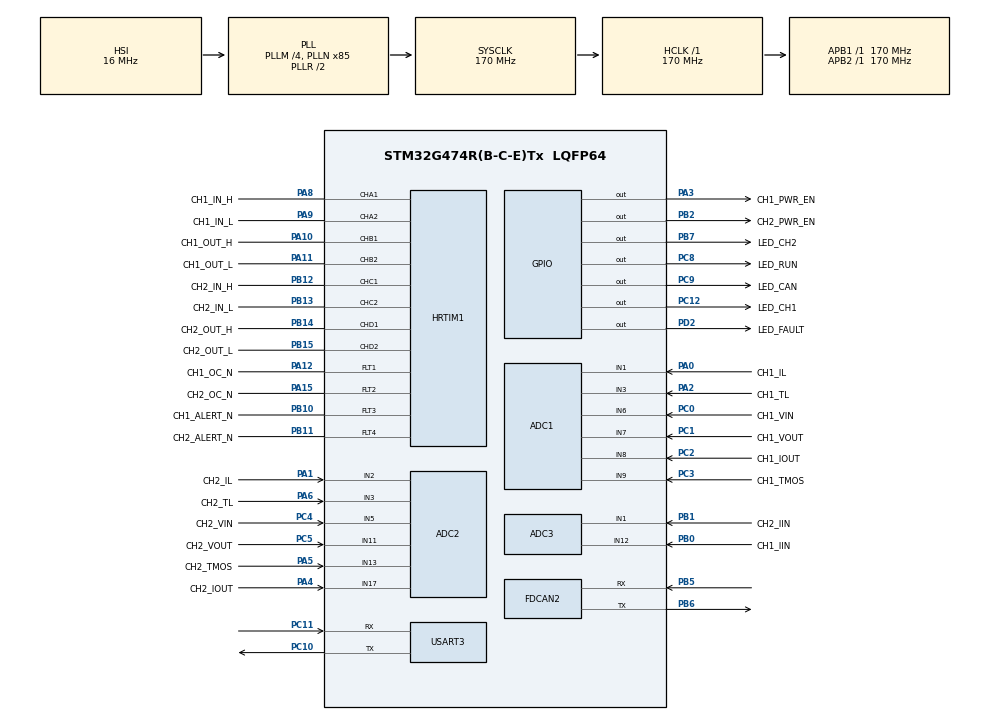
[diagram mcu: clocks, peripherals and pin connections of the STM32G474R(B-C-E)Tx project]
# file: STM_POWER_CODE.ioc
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ADC1.Channel-0\#ChannelRegularConversion=ADC_CHANNEL_6
ADC1.Channel-1\#ChannelRegularConversion=ADC_CHANNEL_7
ADC1.Channel-2\#ChannelRegularConversion=ADC_CHANNEL_8
ADC1.Channel-3\#ChannelRegularConversion=ADC_CHANNEL_9
ADC1.Channel-4\#ChannelRegularConversion=ADC_CHANNEL_3
ADC1.ClockPrescaler=ADC_CLOCK_ASYNC_DIV6
ADC1.ContinuousConvMode=DISABLE
ADC1.DMAContinuousRequests=ENABLE
ADC1.DiscontinuousConvMode=ENABLE
ADC1.EOCSelection=ADC_EOC_SEQ_CONV
ADC1.EnableInjectedConversion=ENABLE
ADC1.ExternalTrigConv=ADC_EXTERNALTRIG_HRTIM_TRG1
ADC1.ExternalTrigInjecConv=ADC_EXTERNALTRIGINJEC_HRTIM_TRG2
ADC1.GainCompensation=0
ADC1.InjNumberOfConversion=1
ADC1.InjectedChannel-6\#ChannelInjectedConversion=ADC_CHANNEL_1
ADC1.InjectedOffsetNumber-6\#ChannelInjectedConversion=ADC_OFFSET_NONE
ADC1.InjectedRank-6\#ChannelInjectedConversion=1
ADC1.InjectedSamplingTime-6\#ChannelInjectedConversion=ADC_SAMPLETIME_24CYCLES_5
ADC1.NbrOfConversion=5
ADC1.NbrOfConversionFlag=1
ADC1.OffsetNumber-0\#ChannelRegularConversion=ADC_OFFSET_NONE
ADC1.OffsetNumber-1\#ChannelRegularConversion=ADC_OFFSET_NONE
ADC1.OffsetNumber-2\#ChannelRegularConversion=ADC_OFFSET_NONE
ADC1.OffsetNumber-3\#ChannelRegularConversion=ADC_OFFSET_NONE
ADC1.OffsetNumber-4\#ChannelRegularConversion=ADC_OFFSET_NONE
ADC1.Rank-0\#ChannelRegularConversion=1
ADC1.Rank-1\#ChannelRegularConversion=2
ADC1.Rank-2\#ChannelRegularConversion=3
ADC1.Rank-3\#ChannelRegularConversion=4
ADC1.Rank-4\#ChannelRegularConversion=5
ADC1.Rank1_Channel=ADC_CHANNEL_1
ADC1.SamplingTime-0\#ChannelRegularConversion=ADC_SAMPLETIME_47CYCLES_5
ADC1.SamplingTime-1\#ChannelRegularConversion=ADC_SAMPLETIME_47CYCLES_5
ADC1.SamplingTime-2\#ChannelRegularConversion=ADC_SAMPLETIME_24CYCLES_5
ADC1.SamplingTime-3\#ChannelRegularConversion=ADC_SAMPLETIME_92CYCLES_5
ADC1.SamplingTime-4\#ChannelRegularConversion=ADC_SAMPLETIME_92CYCLES_5
ADC1.master=1
ADC2.Channel-1\#ChannelRegularConversion=ADC_CHANNEL_5
ADC2.Channel-2\#ChannelRegularConversion=ADC_CHANNEL_11
ADC2.Channel-3\#ChannelRegularConversion=ADC_CHANNEL_17
ADC2.Channel-4\#ChannelRegularConversion=ADC_CHANNEL_13
ADC2.Channel-5\#ChannelRegularConversion=ADC_CHANNEL_3
ADC2.ClockPrescaler=ADC_CLOCK_ASYNC_DIV6
ADC2.DMAContinuousRequests=ENABLE
ADC2.DiscontinuousConvMode=ENABLE
ADC2.EOCSelection=ADC_EOC_SEQ_CONV
ADC2.EnableInjectedConversion=ENABLE
ADC2.ExternalTrigConv=ADC_EXTERNALTRIG_HRTIM_TRG1
ADC2.ExternalTrigInjecConv=ADC_EXTERNALTRIGINJEC_HRTIM_TRG2
ADC2.InjNumberOfConversion=1
ADC2.InjectedChannel-7\#ChannelInjectedConversion=ADC_CHANNEL_2
ADC2.InjectedOffsetNumber-7\#ChannelInjectedConversion=ADC_OFFSET_NONE
ADC2.InjectedRank-7\#ChannelInjectedConversion=1
ADC2.InjectedSamplingTime-7\#ChannelInjectedConversion=ADC_SAMPLETIME_24CYCLES_5
ADC2.NbrOfConversion=5
ADC2.NbrOfConversionFlag=1
ADC2.OffsetNumber-1\#ChannelRegularConversion=ADC_OFFSET_NONE
ADC2.OffsetNumber-2\#ChannelRegularConversion=ADC_OFFSET_NONE
ADC2.OffsetNumber-3\#ChannelRegularConversion=ADC_OFFSET_NONE
ADC2.OffsetNumber-4\#ChannelRegularConversion=ADC_OFFSET_NONE
ADC2.OffsetNumber-5\#ChannelRegularConversion=ADC_OFFSET_NONE
ADC2.Rank-1\#ChannelRegularConversion=1
ADC2.Rank-2\#ChannelRegularConversion=2
ADC2.Rank-3\#ChannelRegularConversion=3
ADC2.Rank-4\#ChannelRegularConversion=4
ADC2.Rank-5\#ChannelRegularConversion=5
ADC2.Rank1_Channel=ADC_CHANNEL_2
ADC2.SamplingTime-1\#ChannelRegularConversion=ADC_SAMPLETIME_47CYCLES_5
ADC2.SamplingTime-2\#ChannelRegularConversion=ADC_SAMPLETIME_47CYCLES_5
ADC2.SamplingTime-3\#ChannelRegularConversion=ADC_SAMPLETIME_24CYCLES_5
ADC2.SamplingTime-4\#ChannelRegularConversion=ADC_SAMPLETIME_92CYCLES_5
ADC2.SamplingTime-5\#ChannelRegularConversion=ADC_SAMPLETIME_92CYCLES_5
ADC3.Channel-0\#ChannelRegularConversion=ADC_CHANNEL_12
ADC3.Channel-1\#ChannelRegularConversion=ADC_CHANNEL_1
ADC3.ClockPrescaler=ADC_CLOCK_ASYNC_DIV6
ADC3.DMAContinuousRequests=ENABLE
ADC3.DiscontinuousConvMode=DISABLE
ADC3.EOCSelection=ADC_EOC_SEQ_CONV
ADC3.ExternalTrigConv=ADC_EXTERNALTRIG_T7_TRGO
ADC3.NbrOfConversion=2
ADC3.NbrOfConversionFlag=1
ADC3.OffsetNumber-0\#ChannelRegularConversion=ADC_OFFSET_NONE
ADC3.OffsetNumber-1\#ChannelRegularConversion=ADC_OFFSET_NONE
ADC3.Rank-0\#ChannelRegularConversion=1
ADC3.Rank-1\#ChannelRegularConversion=2
ADC3.SamplingTime-0\#ChannelRegularConversion=ADC_SAMPLETIME_247CYCLES_5
ADC3.SamplingTime-1\#ChannelRegularConversion=ADC_SAMPLETIME_247CYCLES_5
ADC3.master=1
Dma.ADC1.2.Direction=DMA_PERIPH_TO_MEMORY
Dma.ADC1.2.EventEnable=DISABLE
Dma.ADC1.2.Instance=DMA1_Channel3
Dma.ADC1.2.MemDataAlignment=DMA_MDATAALIGN_HALFWORD
Dma.ADC1.2.MemInc=DMA_MINC_ENABLE
Dma.ADC1.2.Mode=DMA_CIRCULAR
Dma.ADC1.2.PeriphDataAlignment=DMA_PDATAALIGN_HALFWORD
Dma.ADC1.2.PeriphInc=DMA_PINC_DISABLE
Dma.ADC1.2.Polarity=HAL_DMAMUX_REQ_GEN_RISING
Dma.ADC1.2.Priority=DMA_PRIORITY_HIGH
Dma.ADC1.2.RequestNumber=1
Dma.ADC1.2.SignalID=NONE
Dma.ADC1.2.SyncEnable=DISABLE
Dma.ADC1.2.SyncPolarity=HAL_DMAMUX_SYNC_NO_EVENT
Dma.ADC1.2.SyncRequestNumber=1
Dma.ADC1.2.SyncSignalID=NONE
Dma.ADC2.3.Direction=DMA_PERIPH_TO_MEMORY
Dma.ADC2.3.EventEnable=DISABLE
Dma.ADC2.3.Instance=DMA1_Channel4
Dma.ADC2.3.MemDataAlignment=DMA_MDATAALIGN_HALFWORD
Dma.ADC2.3.MemInc=DMA_MINC_ENABLE
Dma.ADC2.3.Mode=DMA_CIRCULAR
Dma.ADC2.3.PeriphDataAlignment=DMA_PDATAALIGN_HALFWORD
Dma.ADC2.3.PeriphInc=DMA_PINC_DISABLE
Dma.ADC2.3.Polarity=HAL_DMAMUX_REQ_GEN_RISING
Dma.ADC2.3.Priority=DMA_PRIORITY_HIGH
Dma.ADC2.3.RequestNumber=1
Dma.ADC2.3.SignalID=NONE
Dma.ADC2.3.SyncEnable=DISABLE
Dma.ADC2.3.SyncPolarity=HAL_DMAMUX_SYNC_NO_EVENT
Dma.ADC2.3.SyncRequestNumber=1
Dma.ADC2.3.SyncSignalID=NONE
Dma.ADC3.4.Direction=DMA_PERIPH_TO_MEMORY
Dma.ADC3.4.EventEnable=DISABLE
Dma.ADC3.4.Instance=DMA1_Channel5
Dma.ADC3.4.MemDataAlignment=DMA_MDATAALIGN_HALFWORD
Dma.ADC3.4.MemInc=DMA_MINC_ENABLE
Dma.ADC3.4.Mode=DMA_CIRCULAR
Dma.ADC3.4.PeriphDataAlignment=DMA_PDATAALIGN_HALFWORD
Dma.ADC3.4.PeriphInc=DMA_PINC_DISABLE
Dma.ADC3.4.Polarity=HAL_DMAMUX_REQ_GEN_RISING
Dma.ADC3.4.Priority=DMA_PRIORITY_HIGH
Dma.ADC3.4.RequestNumber=1
Dma.ADC3.4.SignalID=NONE
Dma.ADC3.4.SyncEnable=DISABLE
Dma.ADC3.4.SyncPolarity=HAL_DMAMUX_SYNC_NO_EVENT
Dma.ADC3.4.SyncRequestNumber=1
Dma.ADC3.4.SyncSignalID=NONE
Dma.Request0=USART3_RX
Dma.Request1=USART3_TX
Dma.Request2=ADC1
Dma.Request3=ADC2
Dma.Request4=ADC3
Dma.USART3_RX.0.Direction=DMA_PERIPH_TO_MEMORY
Dma.USART3_RX.0.EventEnable=DISABLE
Dma.USART3_RX.0.Instance=DMA1_Channel1
Dma.USART3_RX.0.MemDataAlignment=DMA_MDATAALIGN_BYTE
Dma.USART3_RX.0.MemInc=DMA_MINC_ENABLE
Dma.USART3_RX.0.Mode=DMA_CIRCULAR
Dma.USART3_RX.0.PeriphDataAlignment=DMA_PDATAALIGN_BYTE
Dma.USART3_RX.0.PeriphInc=DMA_PINC_DISABLE
Dma.USART3_RX.0.Polarity=HAL_DMAMUX_REQ_GEN_RISING
Dma.USART3_RX.0.Priority=DMA_PRIORITY_MEDIUM
Dma.USART3_RX.0.RequestNumber=1
Dma.USART3_RX.0.SignalID=NONE
Dma.USART3_RX.0.SyncEnable=DISABLE
Dma.USART3_RX.0.SyncPolarity=HAL_DMAMUX_SYNC_NO_EVENT
Dma.USART3_RX.0.SyncRequestNumber=1
Dma.USART3_RX.0.SyncSignalID=NONE
Dma.USART3_TX.1.Direction=DMA_MEMORY_TO_PERIPH
Dma.USART3_TX.1.EventEnable=DISABLE
Dma.USART3_TX.1.Instance=DMA1_Channel2
Dma.USART3_TX.1.MemDataAlignment=DMA_MDATAALIGN_BYTE
Dma.USART3_TX.1.MemInc=DMA_MINC_ENABLE
Dma.USART3_TX.1.Mode=DMA_NORMAL
Dma.USART3_TX.1.PeriphDataAlignment=DMA_PDATAALIGN_BYTE
Dma.USART3_TX.1.PeriphInc=DMA_PINC_DISABLE
Dma.USART3_TX.1.Polarity=HAL_DMAMUX_REQ_GEN_RISING
Dma.USART3_TX.1.Priority=DMA_PRIORITY_LOW
Dma.USART3_TX.1.RequestNumber=1
Dma.USART3_TX.1.SignalID=NONE
Dma.USART3_TX.1.SyncEnable=DISABLE
Dma.USART3_TX.1.SyncPolarity=HAL_DMAMUX_SYNC_NO_EVENT
Dma.USART3_TX.1.SyncRequestNumber=1
Dma.USART3_TX.1.SyncSignalID=NONE
FDCAN2.CalculateBaudRateNominal=499999
FDCAN2.CalculateTimeBitNominal=2000
FDCAN2.CalculateTimeQuantumNominal=23.529411764705884
FDCAN2.NominalPrescaler=1
FDCAN2.NominalSyncJumpWidth=8
FDCAN2.NominalTimeSeg1=67
FDCAN2.NominalTimeSeg2=17
FDCAN2.StdFiltersNbr=1
FREERTOS.Tasks01=defaultTask,24,1024,StartDefaultTask,Default,NULL,Dynamic,NULL,NULL
FREERTOS.configCHECK_FOR_STACK_OVERFLOW=2
FREERTOS.configTOTAL_HEAP_SIZE=16384
FREERTOS.configUSE_MALLOC_FAILED_HOOK=1
HRTIM1.ADCTrigger1_Source1=HRTIM_ADCTRIGGEREVENT13_TIMERE_CMP3
HRTIM1.ADCTrigger2_Source1=HRTIM_ADCTRIGGEREVENT24_TIMERE_CMP2
HRTIM1.ADCTrigger_Id1=HRTIM_ADCTRIGGER_1
HRTIM1.ADCTrigger_Id2=HRTIM_ADCTRIGGER_2
HRTIM1.AutoDelayedMode2-No_output_TE=HRTIM_AUTODELAYEDMODE_REGULAR
HRTIM1.BlankingSourceFaultLine1=__NULL
HRTIM1.BlankingSourceFaultLine2=__NULL
HRTIM1.BlankingSourceFaultLine3=__NULL
HRTIM1.BlankingSourceFaultLine4=__NULL
HRTIM1.CompareUnit1-Output_TA1TA2=HRTIM_COMPAREUNIT_1
HRTIM1.CompareUnit1-Output_TB1TB2=HRTIM_COMPAREUNIT_1
HRTIM1.CompareUnit1-Output_TC1TC2=HRTIM_COMPAREUNIT_1
HRTIM1.CompareUnit1-Output_TD1TD2=HRTIM_COMPAREUNIT_1
HRTIM1.CompareUnit2-No_output_TE=HRTIM_COMPAREUNIT_2
HRTIM1.CompareUnit3-No_output_TE=HRTIM_COMPAREUNIT_3
HRTIM1.CompareValue1-Output_TA1TA2=0x2A80
HRTIM1.CompareValue1-Output_TB1TB2=0x2A80
HRTIM1.CompareValue1-Output_TC1TC2=0x2A80
HRTIM1.CompareValue1-Output_TD1TD2=0x2A80
HRTIM1.CompareValue2-No_output_TE=0x7F80
HRTIM1.CompareValue3-No_output_TE=0x2A80
HRTIM1.DeadTimeInsertion-Output_TA1TA2=HRTIM_TIMDEADTIMEINSERTION_ENABLED
HRTIM1.DeadTimeInsertion-Output_TB1TB2=HRTIM_TIMDEADTIMEINSERTION_ENABLED
HRTIM1.DeadTimeInsertion-Output_TC1TC2=HRTIM_TIMDEADTIMEINSERTION_ENABLED
HRTIM1.DeadTimeInsertion-Output_TD1TD2=HRTIM_TIMDEADTIMEINSERTION_ENABLED
HRTIM1.FallingValue-Output_TA1TA2=0x014
HRTIM1.FallingValue-Output_TB1TB2=0x014
HRTIM1.FallingValue-Output_TC1TC2=0x014
HRTIM1.FallingValue-Output_TD1TD2=0x014
HRTIM1.FaultEnable_Source1-Output_TA1TA2=HRTIM_TIMFAULTENABLE_FAULT1
HRTIM1.FaultEnable_Source1-Output_TB1TB2=HRTIM_TIMFAULTENABLE_FAULT1
HRTIM1.FaultEnable_Source1-Output_TC1TC2=HRTIM_TIMFAULTENABLE_FAULT2
HRTIM1.FaultEnable_Source1-Output_TD1TD2=HRTIM_TIMFAULTENABLE_FAULT2
HRTIM1.FaultEnable_Source2-Output_TA1TA2=HRTIM_TIMFAULTENABLE_FAULT3
HRTIM1.FaultEnable_Source2-Output_TB1TB2=HRTIM_TIMFAULTENABLE_FAULT3
HRTIM1.FaultEnable_Source2-Output_TC1TC2=HRTIM_TIMFAULTENABLE_FAULT4
HRTIM1.FaultEnable_Source2-Output_TD1TD2=HRTIM_TIMFAULTENABLE_FAULT4
HRTIM1.FaultLevel1-Output_TA1TA2=HRTIM_OUTPUTFAULTLEVEL_INACTIVE
HRTIM1.FaultLevel1-Output_TB1TB2=HRTIM_OUTPUTFAULTLEVEL_INACTIVE
HRTIM1.FaultLevel1-Output_TC1TC2=HRTIM_OUTPUTFAULTLEVEL_INACTIVE
HRTIM1.FaultLevel1-Output_TD1TD2=HRTIM_OUTPUTFAULTLEVEL_INACTIVE
HRTIM1.FaultLevel2-Output_TA1TA2=HRTIM_OUTPUTFAULTLEVEL_INACTIVE
HRTIM1.FaultLevel2-Output_TB1TB2=HRTIM_OUTPUTFAULTLEVEL_INACTIVE
HRTIM1.FaultLevel2-Output_TC1TC2=HRTIM_OUTPUTFAULTLEVEL_INACTIVE
HRTIM1.FaultLevel2-Output_TD1TD2=HRTIM_OUTPUTFAULTLEVEL_INACTIVE
HRTIM1.HRTIMInterruptResquests1=HRTIM_IT_FLT1
HRTIM1.HRTIMInterruptResquests2=HRTIM_IT_FLT2
HRTIM1.HRTIMInterruptResquests3=HRTIM_IT_FLT3
HRTIM1.HRTIMInterruptResquests4=HRTIM_IT_FLT4
HRTIM1.IdleMode1-Output_TA1TA2=HRTIM_OUTPUTIDLEMODE_IDLE
HRTIM1.IdleMode1-Output_TB1TB2=HRTIM_OUTPUTIDLEMODE_IDLE
HRTIM1.IdleMode1-Output_TC1TC2=HRTIM_OUTPUTIDLEMODE_IDLE
HRTIM1.IdleMode1-Output_TD1TD2=HRTIM_OUTPUTIDLEMODE_IDLE
HRTIM1.IdleMode2-Output_TA1TA2=HRTIM_OUTPUTIDLEMODE_IDLE
HRTIM1.IdleMode2-Output_TB1TB2=HRTIM_OUTPUTIDLEMODE_IDLE
HRTIM1.IdleMode2-Output_TC1TC2=HRTIM_OUTPUTIDLEMODE_IDLE
HRTIM1.IdleMode2-Output_TD1TD2=HRTIM_OUTPUTIDLEMODE_IDLE
HRTIM1.NumberADCTriggerSource1=1
HRTIM1.NumberADCTriggerSource2=1
HRTIM1.NumberFaultEnable-Output_TA1TA2=2
HRTIM1.NumberFaultEnable-Output_TB1TB2=2
HRTIM1.NumberFaultEnable-Output_TC1TC2=2
HRTIM1.NumberFaultEnable-Output_TD1TD2=2
HRTIM1.NumberResetSource1-Output_TA1TA2=1
HRTIM1.NumberResetSource1-Output_TB1TB2=1
HRTIM1.NumberResetSource1-Output_TC1TC2=1
HRTIM1.NumberResetSource1-Output_TD1TD2=1
HRTIM1.NumberResetTrigger-Output_TA1TA2=1
HRTIM1.NumberResetTrigger-Output_TB1TB2=1
HRTIM1.NumberResetTrigger-Output_TC1TC2=1
HRTIM1.NumberResetTrigger-Output_TD1TD2=1
HRTIM1.NumberSetSource1-Output_TA1TA2=1
HRTIM1.NumberSetSource1-Output_TB1TB2=1
HRTIM1.NumberSetSource1-Output_TC1TC2=1
HRTIM1.NumberSetSource1-Output_TD1TD2=1
HRTIM1.NumberUpdateTrigger-Output_TA1TA2=1
HRTIM1.NumberUpdateTrigger-Output_TB1TB2=1
HRTIM1.NumberUpdateTrigger-Output_TC1TC2=1
HRTIM1.NumberUpdateTrigger-Output_TD1TD2=1
HRTIM1.ORingUpdateSource_ADCTrigger1=HRTIM_ADCTRIGGERUPDATE_TIMER_E
HRTIM1.ORingUpdateSource_ADCTrigger2=HRTIM_ADCTRIGGERUPDATE_TIMER_E
HRTIM1.Periode_MASTER=0x5500
HRTIM1.Periode_TA=0x5500
HRTIM1.Periode_TB=0x5500
HRTIM1.Periode_TC=0x5500
HRTIM1.Periode_TD=0x5500
HRTIM1.Periode_TE=0xAA00
HRTIM1.Polarity_FaultLine1=HRTIM_FAULTPOLARITY_LOW
HRTIM1.Polarity_FaultLine2=HRTIM_FAULTPOLARITY_LOW
HRTIM1.Polarity_FaultLine3=HRTIM_FAULTPOLARITY_LOW
HRTIM1.Polarity_FaultLine4=HRTIM_FAULTPOLARITY_LOW
HRTIM1.PreloadEnable-MasterTimer=HRTIM_PRELOAD_ENABLED
HRTIM1.PreloadEnable-Output_TA1TA2=HRTIM_PRELOAD_ENABLED
HRTIM1.PreloadEnable-Output_TB1TB2=HRTIM_PRELOAD_ENABLED
HRTIM1.PreloadEnable-Output_TC1TC2=HRTIM_PRELOAD_ENABLED
HRTIM1.PreloadEnable-Output_TD1TD2=HRTIM_PRELOAD_ENABLED
HRTIM1.PrescalerDead-Output_TA1TA2=HRTIM_TIMDEADTIME_PRESCALERRATIO_DIV1
HRTIM1.PrescalerDead-Output_TB1TB2=HRTIM_TIMDEADTIME_PRESCALERRATIO_DIV1
HRTIM1.PrescalerDead-Output_TC1TC2=HRTIM_TIMDEADTIME_PRESCALERRATIO_DIV1
HRTIM1.PrescalerDead-Output_TD1TD2=HRTIM_TIMDEADTIME_PRESCALERRATIO_DIV1
HRTIM1.RepetitionUpdate-MasterTimer=HRTIM_UPDATEONREPETITION_ENABLED
HRTIM1.ResetOutput1_Source1-Output_TA1TA2=HRTIM_OUTPUTRESET_TIMCMP1
HRTIM1.ResetOutput1_Source1-Output_TB1TB2=HRTIM_OUTPUTRESET_TIMCMP1
HRTIM1.ResetOutput1_Source1-Output_TC1TC2=HRTIM_OUTPUTRESET_TIMCMP1
HRTIM1.ResetOutput1_Source1-Output_TD1TD2=HRTIM_OUTPUTRESET_TIMCMP1
HRTIM1.ResetTrigger1-Output_TA1TA2=HRTIM_TIMRESETTRIGGER_MASTER_PER
HRTIM1.ResetTrigger1-Output_TB1TB2=HRTIM_TIMRESETTRIGGER_MASTER_PER
HRTIM1.ResetTrigger1-Output_TC1TC2=HRTIM_TIMRESETTRIGGER_MASTER_PER
HRTIM1.ResetTrigger1-Output_TD1TD2=HRTIM_TIMRESETTRIGGER_MASTER_PER
HRTIM1.ResetUpdate-Output_TA1TA2=HRTIM_TIMUPDATEONRESET_DISABLED
HRTIM1.RisingValue-Output_TA1TA2=0x014
HRTIM1.RisingValue-Output_TB1TB2=0x014
HRTIM1.RisingValue-Output_TC1TC2=0x014
HRTIM1.RisingValue-Output_TD1TD2=0x014
HRTIM1.SetOutput1_Source1-Output_TA1TA2=HRTIM_OUTPUTSET_MASTERPER
HRTIM1.SetOutput1_Source1-Output_TB1TB2=HRTIM_OUTPUTSET_MASTERPER
HRTIM1.SetOutput1_Source1-Output_TC1TC2=HRTIM_OUTPUTSET_MASTERPER
HRTIM1.SetOutput1_Source1-Output_TD1TD2=HRTIM_OUTPUTSET_MASTERPER
HRTIM1.UpdateTrigger1-Output_TA1TA2=HRTIM_TIMUPDATETRIGGER_MASTER
HRTIM1.UpdateTrigger1-Output_TB1TB2=HRTIM_TIMUPDATETRIGGER_MASTER
HRTIM1.UpdateTrigger1-Output_TC1TC2=HRTIM_TIMUPDATETRIGGER_MASTER
HRTIM1.UpdateTrigger1-Output_TD1TD2=HRTIM_TIMUPDATETRIGGER_MASTER
Mcu.Family=STM32G4
Mcu.Name=STM32G474R(B-C-E)Tx
Mcu.Package=LQFP64
NVIC.ADC1_2_IRQn=true\:4\:0\:true\:false\:true\:false\:true\:true\:true
NVIC.ADC3_IRQn=true\:6\:0\:true\:false\:true\:true\:true\:true\:true
NVIC.DMA1_Channel1_IRQn=true\:6\:0\:true\:false\:true\:true\:false\:true\:true
NVIC.DMA1_Channel2_IRQn=true\:6\:0\:true\:false\:true\:true\:false\:true\:true
NVIC.DMA1_Channel3_IRQn=true\:6\:0\:true\:false\:true\:true\:false\:true\:true
NVIC.DMA1_Channel4_IRQn=true\:6\:0\:true\:false\:true\:true\:false\:true\:true
NVIC.DMA1_Channel5_IRQn=true\:6\:0\:true\:false\:true\:true\:false\:true\:true
NVIC.FDCAN2_IT0_IRQn=true\:6\:0\:true\:false\:true\:true\:true\:true\:true
NVIC.FDCAN2_IT1_IRQn=true\:6\:0\:true\:false\:true\:true\:true\:true\:true
NVIC.HRTIM1_FLT_IRQn=true\:0\:0\:true\:false\:true\:false\:true\:true\:true
NVIC.PriorityGroup=NVIC_PRIORITYGROUP_4
NVIC.TIM6_DAC_IRQn=true\:15\:0\:false\:false\:true\:false\:false\:true\:true
NVIC.TimeBase=TIM6_DAC_IRQn
NVIC.TimeBaseIP=TIM6
NVIC.USART3_IRQn=true\:6\:0\:true\:false\:true\:true\:true\:true\:true
PA0.GPIO_Label=CH1_IL
PA0.Mode=IN1-Single-Ended
PA0.Signal=ADC1_IN1
PA1.GPIO_Label=CH2_IL
PA1.Mode=IN2-Single-Ended
PA1.Signal=ADC2_IN2
PA10.GPIO_Label=CH1_OUT_H
PA10.Mode=Output_TB1TB2
PA10.Signal=HRTIM1_CHB1
PA11.GPIO_Label=CH1_OUT_L
PA11.Mode=Output_TB1TB2
PA11.Signal=HRTIM1_CHB2
PA12.GPIO_Label=CH1_OC_N
PA12.Mode=Fault_Enable1
PA12.Signal=HRTIM1_FLT1
PA13.Mode=Serial_Wire
PA13.Signal=SYS_JTMS-SWDIO
PA14.Mode=Serial_Wire
PA14.Signal=SYS_JTCK-SWCLK
PA15.GPIO_Label=CH2_OC_N
PA15.Mode=Fault_Enable2
PA15.Signal=HRTIM1_FLT2
PA2.GPIO_Label=CH1_TL
PA2.Mode=IN3-Single-Ended
PA2.Signal=ADC1_IN3
PA3.GPIO_Label=CH1_PWR_EN
PA3.GPIO_ModeDefaultOutputPP=GPIO_MODE_OUTPUT_PP
PA3.GPIO_PuPd=GPIO_NOPULL
PA3.GPIO_Speed=GPIO_SPEED_FREQ_LOW
PA3.PinState=GPIO_PIN_RESET
PA3.Signal=GPIO_Output
PA4.GPIO_Label=CH2_IOUT
PA4.Mode=IN17-Single-Ended
PA4.Signal=ADC2_IN17
PA5.GPIO_Label=CH2_TMOS
PA5.Mode=IN13-Single-Ended
PA5.Signal=ADC2_IN13
PA6.GPIO_Label=CH2_TL
PA6.Mode=IN3-Single-Ended
PA6.Signal=ADC2_IN3
PA8.GPIO_Label=CH1_IN_H
PA8.Mode=Output_TA1TA2
PA8.Signal=HRTIM1_CHA1
PA9.GPIO_Label=CH1_IN_L
PA9.Mode=Output_TA1TA2
PA9.Signal=HRTIM1_CHA2
PB0.GPIO_Label=CH1_IIN
PB0.Mode=IN12-Single-Ended
PB0.Signal=ADC3_IN12
PB1.GPIO_Label=CH2_IIN
PB1.Mode=IN1-Single-Ended
PB1.Signal=ADC3_IN1
PB10.GPIO_Label=CH1_ALERT_N
PB10.Mode=Fault_Enable3
PB10.Signal=HRTIM1_FLT3
PB11.GPIO_Label=CH2_ALERT_N
PB11.Mode=Fault_Enable4
PB11.Signal=HRTIM1_FLT4
PB12.GPIO_Label=CH2_IN_H
PB12.Mode=Output_TC1TC2
PB12.Signal=HRTIM1_CHC1
PB13.GPIO_Label=CH2_IN_L
PB13.Mode=Output_TC1TC2
PB13.Signal=HRTIM1_CHC2
PB14.GPIO_Label=CH2_OUT_H
PB14.Mode=Output_TD1TD2
PB14.Signal=HRTIM1_CHD1
PB15.GPIO_Label=CH2_OUT_L
PB15.Mode=Output_TD1TD2
PB15.Signal=HRTIM1_CHD2
PB2.GPIO_Label=CH2_PWR_EN
PB2.GPIO_ModeDefaultOutputPP=GPIO_MODE_OUTPUT_PP
PB2.GPIO_PuPd=GPIO_NOPULL
PB2.GPIO_Speed=GPIO_SPEED_FREQ_LOW
PB2.PinState=GPIO_PIN_RESET
PB2.Signal=GPIO_Output
PB5.Mode=FDCAN_Activate
PB5.Signal=FDCAN2_RX
PB6.GPIO_Speed=GPIO_SPEED_FREQ_HIGH
PB6.Mode=FDCAN_Activate
PB6.Signal=FDCAN2_TX
PB7.GPIO_Label=LED_CH2
PB7.GPIO_ModeDefaultOutputPP=GPIO_MODE_OUTPUT_PP
PB7.GPIO_PuPd=GPIO_NOPULL
PB7.GPIO_Speed=GPIO_SPEED_FREQ_LOW
PB7.PinState=GPIO_PIN_RESET
PB7.Signal=GPIO_Output
PC0.GPIO_Label=CH1_VIN
PC0.Mode=IN6-Single-Ended
PC0.Signal=ADC1_IN6
PC1.GPIO_Label=CH1_VOUT
PC1.Mode=IN7-Single-Ended
PC1.Signal=ADC1_IN7
PC10.GPIO_Speed=GPIO_SPEED_FREQ_HIGH
PC10.Mode=Asynchronous
PC10.Signal=USART3_TX
PC11.Mode=Asynchronous
PC11.Signal=USART3_RX
PC12.GPIO_Label=LED_CH1
PC12.GPIO_ModeDefaultOutputPP=GPIO_MODE_OUTPUT_PP
PC12.GPIO_PuPd=GPIO_NOPULL
PC12.GPIO_Speed=GPIO_SPEED_FREQ_LOW
PC12.PinState=GPIO_PIN_RESET
PC12.Signal=GPIO_Output
PC14-OSC32_IN.Mode=LSE-External-Oscillator
PC14-OSC32_IN.Signal=RCC_OSC32_IN
PC15-OSC32_OUT.Mode=LSE-External-Oscillator
PC15-OSC32_OUT.Signal=RCC_OSC32_OUT
PC2.GPIO_Label=CH1_IOUT
PC2.Mode=IN8-Single-Ended
PC2.Signal=ADC1_IN8
PC3.GPIO_Label=CH1_TMOS
PC3.Mode=IN9-Single-Ended
PC3.Signal=ADC1_IN9
PC4.GPIO_Label=CH2_VIN
PC4.Mode=IN5-Single-Ended
PC4.Signal=ADC2_IN5
PC5.GPIO_Label=CH2_VOUT
PC5.Mode=IN11-Single-Ended
PC5.Signal=ADC2_IN11
PC8.GPIO_Label=LED_RUN
PC8.GPIO_ModeDefaultOutputPP=GPIO_MODE_OUTPUT_PP
PC8.GPIO_PuPd=GPIO_NOPULL
PC8.GPIO_Speed=GPIO_SPEED_FREQ_LOW
PC8.PinState=GPIO_PIN_RESET
PC8.Signal=GPIO_Output
PC9.GPIO_Label=LED_CAN
PC9.GPIO_ModeDefaultOutputPP=GPIO_MODE_OUTPUT_PP
PC9.GPIO_PuPd=GPIO_NOPULL
PC9.GPIO_Speed=GPIO_SPEED_FREQ_LOW
PC9.PinState=GPIO_PIN_RESET
PC9.Signal=GPIO_Output
PD2.GPIO_Label=LED_FAULT
PD2.GPIO_ModeDefaultOutputPP=GPIO_MODE_OUTPUT_PP
PD2.GPIO_PuPd=GPIO_NOPULL
PD2.GPIO_Speed=GPIO_SPEED_FREQ_LOW
PD2.PinState=GPIO_PIN_RESET
PD2.Signal=GPIO_Output
PF0-OSC_IN.Mode=HSE-External-Oscillator
PF0-OSC_IN.Signal=RCC_OSC_IN
PF1-OSC_OUT.Mode=HSE-External-Oscillator
PF1-OSC_OUT.Signal=RCC_OSC_OUT
ProjectManager.HeapSize=0x200
ProjectManager.StackSize=0x1000
ProjectManager.TargetToolchain=MDK-ARM V5.32
RCC.ADC12Freq_Value=170000000
RCC.ADC345Freq_Value=170000000
RCC.AHBFreq_Value=170000000
RCC.APB1Freq_Value=170000000
RCC.APB1TimFreq_Value=170000000
RCC.APB2Freq_Value=170000000
RCC.APB2TimFreq_Value=170000000
RCC.CortexFreq_Value=170000000
RCC.EXTERNAL_CLOCK_VALUE=12288000
RCC.FDCANCLockSelection=RCC_FDCANCLKSOURCE_PLL
RCC.HCLKFreq_Value=170000000
RCC.HSE_VALUE=8000000
RCC.HSI48_VALUE=48000000
RCC.HSI_VALUE=16000000
RCC.PLLM=RCC_PLLM_DIV4
RCC.PLLN=85
RCC.PLLQ=RCC_PLLQ_DIV8
RCC.SYSCLKFreq_VALUE=170000000
RCC.SYSCLKSource=RCC_SYSCLKSOURCE_PLLCLK
RCC.USBFreq_Value=42500000
RCC.VCOOutputFreq_Value=340000000
TIM7.AutoReloadPreload=TIM_AUTORELOAD_PRELOAD_ENABLE
TIM7.PeriodNoDither=999
TIM7.Prescaler=169
TIM7.TIM_MasterOutputTrigger=TIM_TRGO_UPDATE
USART3.VirtualMode-Asynchronous=VM_ASYNC
VP_FREERTOS_VS_CMSIS_V2.Mode=CMSIS_V2
VP_HRTIM1_VS_hrtimMasterTimerNoOutput.Mode=MasterTimer
VP_HRTIM1_VS_hrtimTimerENoOutput.Mode=No_output_TE
VP_SYS_VS_DBSignals.Mode=DisableDeadBatterySignals
VP_SYS_VS_tim6.Mode=TIM6
VP_TIM7_VS_ClockSourceINT.Mode=Enable_Timer
board=custom

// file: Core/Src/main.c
/* USER CODE BEGIN Header */
/**
  ******************************************************************************
  * @file           : main.c
  * @brief          : Main program body
  ******************************************************************************
  * @attention
  *
  * Copyright (c) 2026 STMicroelectronics.
  * All rights reserved.
  *
  * This software is licensed under terms that can be found in the LICENSE file
  * in the root directory of this software component.
  * If no LICENSE file comes with this software, it is provided AS-IS.
  *
  ******************************************************************************
  */
/* USER CODE END Header */
#include "main.h"
#include "cmsis_os.h"
#include "adc.h"
#include "dma.h"
#include "fdcan.h"
#include "hrtim.h"
#include "tim.h"
#include "usart.h"
#include "gpio.h"

/* USER CODE BEGIN Includes */
#include "pd_board.h"
/* USER CODE END Includes */

void SystemClock_Config(void);
void MX_FREERTOS_Init(void);

int main(void)
{

  /* MCU Configuration--------------------------------------------------------*/

  /* Reset of all peripherals, Initializes the Flash interface and the Systick. */
  HAL_Init();

  /* Configure the system clock */
  SystemClock_Config();

  /* Initialize all configured peripherals */
  MX_GPIO_Init();
  MX_DMA_Init();
  MX_USART3_UART_Init();
  MX_ADC1_Init();
  MX_ADC2_Init();
  MX_ADC3_Init();
  MX_FDCAN2_Init();
  MX_HRTIM1_Init();
  MX_TIM7_Init();
  /* USER CODE BEGIN 2 */
  PD_BoardInit();
  /* USER CODE END 2 */

  /* Init scheduler */
  osKernelInitialize();  /* Call init function for freertos objects (in cmsis_os2.c) */
  MX_FREERTOS_Init();

  /* Start scheduler */
  osKernelStart();

  /* We should never get here as control is now taken by the scheduler */

  /* Infinite loop */
  while (1)
  {

  }
}

void SystemClock_Config(void)
{
  RCC_OscInitTypeDef RCC_OscInitStruct = {0};
  RCC_ClkInitTypeDef RCC_ClkInitStruct = {0};

  /** Configure the main internal regulator output voltage
  */
  HAL_PWREx_ControlVoltageScaling(PWR_REGULATOR_VOLTAGE_SCALE1_BOOST);

  /** Initializes the RCC Oscillators according to the specified parameters
  * in the RCC_OscInitTypeDef structure.
  */
  RCC_OscInitStruct.OscillatorType = RCC_OSCILLATORTYPE_HSI;
  RCC_OscInitStruct.HSIState = RCC_HSI_ON;
  RCC_OscInitStruct.HSICalibrationValue = RCC_HSICALIBRATION_DEFAULT;
  RCC_OscInitStruct.PLL.PLLState = RCC_PLL_ON;
  RCC_OscInitStruct.PLL.PLLSource = RCC_PLLSOURCE_HSI;
  RCC_OscInitStruct.PLL.PLLM = RCC_PLLM_DIV4;
  RCC_OscInitStruct.PLL.PLLN = 85;
  RCC_OscInitStruct.PLL.PLLP = RCC_PLLP_DIV2;
  RCC_OscInitStruct.PLL.PLLQ = RCC_PLLQ_DIV8;
  RCC_OscInitStruct.PLL.PLLR = RCC_PLLR_DIV2;
  if (HAL_RCC_OscConfig(&RCC_OscInitStruct) != HAL_OK)
  {
    Error_Handler();
  }

  /** Initializes the CPU, AHB and APB buses clocks
  */
  RCC_ClkInitStruct.ClockType = RCC_CLOCKTYPE_HCLK|RCC_CLOCKTYPE_SYSCLK
                              |RCC_CLOCKTYPE_PCLK1|RCC_CLOCKTYPE_PCLK2;
  RCC_ClkInitStruct.SYSCLKSource = RCC_SYSCLKSOURCE_PLLCLK;
  RCC_ClkInitStruct.AHBCLKDivider = RCC_SYSCLK_DIV1;
  RCC_ClkInitStruct.APB1CLKDivider = RCC_HCLK_DIV1;
  RCC_ClkInitStruct.APB2CLKDivider = RCC_HCLK_DIV1;

  if (HAL_RCC_ClockConfig(&RCC_ClkInitStruct, FLASH_LATENCY_4) != HAL_OK)
  {
    Error_Handler();
  }
}

void HAL_TIM_PeriodElapsedCallback(TIM_HandleTypeDef *htim)
{
  if (htim->Instance == TIM6)
  {
    HAL_IncTick();
  }
}

void Error_Handler(void)
{
  /* USER CODE BEGIN Error_Handler_Debug */
  PD_BoardEmergencyStop();
  __disable_irq();
  while (1) {}
  /* USER CODE END Error_Handler_Debug */
}

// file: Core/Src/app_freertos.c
/* USER CODE BEGIN Header */
/**
  ******************************************************************************
  * File Name          : app_freertos.c
  * Description        : Code for freertos applications
  ******************************************************************************
  * @attention
  *
  * Copyright (c) 2026 STMicroelectronics.
  * All rights reserved.
  *
  * This software is licensed under terms that can be found in the LICENSE file
  * in the root directory of this software component.
  * If no LICENSE file comes with this software, it is provided AS-IS.
  *
  ******************************************************************************
  */
/* USER CODE END Header */

#include "FreeRTOS.h"
#include "task.h"
#include "main.h"
#include "cmsis_os.h"
#include "pd_can_port.h"
#include "pd_core.h"

/* USER CODE BEGIN Includes */
#include "pd_board.h"
/* USER CODE END Includes */

/* Definitions for defaultTask */
osThreadId_t defaultTaskHandle;
const osThreadAttr_t defaultTask_attributes = {
  .name = "defaultTask",
  .priority = (osPriority_t) osPriorityNormal,
  .stack_size = 1024 * 4
};

void StartDefaultTask(void *argument);

void MX_FREERTOS_Init(void); /* (MISRA C 2004 rule 8.1) */

/* Hook prototypes */
void vApplicationStackOverflowHook(xTaskHandle xTask, signed char *pcTaskName);
void vApplicationMallocFailedHook(void);

/* USER CODE BEGIN 4 */
void vApplicationStackOverflowHook(xTaskHandle xTask, signed char *pcTaskName)
{
  (void)xTask; (void)pcTaskName; PD_BoardEmergencyStop(); __disable_irq(); for (;;) {}
}
/* USER CODE END 4 */

/* USER CODE BEGIN 5 */
void vApplicationMallocFailedHook(void)
{
  PD_BoardEmergencyStop(); __disable_irq(); for (;;) {}
}
/* USER CODE END 5 */

void MX_FREERTOS_Init(void) {

  /* Create the thread(s) */
  /* creation of defaultTask */
  defaultTaskHandle = osThreadNew(StartDefaultTask, NULL, &defaultTask_attributes);

  /* USER CODE BEGIN RTOS_THREADS */
  if (defaultTaskHandle == NULL) { Error_Handler(); }
  /* USER CODE END RTOS_THREADS */

}

void StartDefaultTask(void *argument)
{
  /* USER CODE BEGIN StartDefaultTask */
  (void)argument;
  /* Bring up the CAN endpoint before the loop so a HMI that is already
     talking gets its capability frames as soon as the bus is up. */
  if (PD_CanPortInit() != 0)
  {
    PD_Log(0, 2, 21, "CAN init failed; serial control only");
  }
  else
  {
    PD_CanPortAnnounce();
  }
  for (;;) { PD_BoardPoll(); PD_CanPortPoll(); osDelay(1); }
  /* USER CODE END StartDefaultTask */
}
